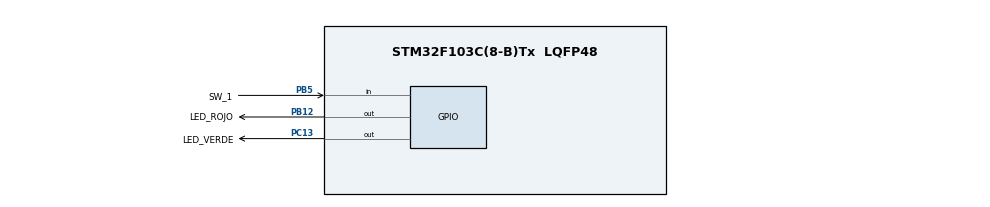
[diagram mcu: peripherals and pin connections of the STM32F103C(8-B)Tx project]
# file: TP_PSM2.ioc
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Mcu.Family=STM32F1
Mcu.Name=STM32F103C(8-B)Tx
Mcu.Package=LQFP48
NVIC.PriorityGroup=NVIC_PRIORITYGROUP_4
PA13.Mode=Serial_Wire
PA13.Signal=SYS_JTMS-SWDIO
PA14.Mode=Serial_Wire
PA14.Signal=SYS_JTCK-SWCLK
PB12.GPIO_Label=LED_ROJO
PB12.GPIO_PuPd=GPIO_NOPULL
PB12.Signal=GPIO_Output
PB5.GPIO_Label=SW_1
PB5.GPIO_PuPd=GPIO_PULLDOWN
PB5.Signal=GPIO_Input
PC13-TAMPER-RTC.GPIO_Label=LED_VERDE
PC13-TAMPER-RTC.GPIO_PuPd=GPIO_NOPULL
PC13-TAMPER-RTC.Signal=GPIO_Output
ProjectManager.HeapSize=0x200
ProjectManager.StackSize=0x400
ProjectManager.TargetToolchain=STM32CubeIDE
RCC.APB1Freq_Value=8000000
RCC.APB2Freq_Value=8000000
board=custom

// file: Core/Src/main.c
/* USER CODE BEGIN Header */
/**
  ******************************************************************************
  * @file           : main.c
  * @brief          : Main program body
  ******************************************************************************
  * @attention
  *
  * Copyright (c) 2024 STMicroelectronics.
  * All rights reserved.
  *
  ******************************************************************************
  */
/* USER CODE END Header */
#include "main.h"

/* USER CODE BEGIN Includes */
#include "fsm.h"
#include "timer.h"
/* USER CODE END Includes */

Semaforo semaforo;
Timer timer;  // Timer utilizado para manejar tiempos de transición

void SystemClock_Config(void);
static void MX_GPIO_Init(void);

/* USER CODE BEGIN 0 */

/***********************************************
*        PASO 4: FUNCIONES DE TRANSICIÓN       *
***********************************************/

/**
 * @brief Condición para pasar de verde a verde parpadeante.
 */
static int condicion_verde_a_verde_parpadeo(void *context) {
    Semaforo *semaforo = (Semaforo *)context;
    return (semaforo->fsm.currentState == ESTADO_VERDE) &&
           (HAL_GPIO_ReadPin(semaforo->PortSwitch, semaforo->PinSwitch) == GPIO_PIN_SET);
}

/**
 * @brief Condición para pasar de verde parpadeante a rojo.
 */
static int condicion_verde_parpadeo_a_rojo(void *context) {
    Semaforo *semaforo = (Semaforo *)context;
    return timer_has_expired(semaforo->timer);
}

/**
 * @brief Condición para pasar de rojo a rojo parpadeante.
 */
static int condicion_rojo_a_rojo_parpadeo(void *context) {
    Semaforo *semaforo = (Semaforo *)context;
    return timer_has_expired(semaforo->timer);
}

/**
 * @brief Condición para pasar de rojo parpadeante a verde.
 */
static int condicion_rojo_parpadeo_a_verde(void *context) {
    Semaforo *semaforo = (Semaforo *)context;
    return timer_has_expired(semaforo->timer);
}

/***********************************************
*          PASO 5: FUNCIONES DE ACCIÓN         *
***********************************************/

/**
 * @brief Acción al entrar en el estado verde.
 */
void on_state_verde(void *context) {
    Semaforo *semaforo = (Semaforo *)context;
    HAL_GPIO_WritePin(semaforo->PortVerde, semaforo->PinVerde, GPIO_PIN_RESET);
    HAL_GPIO_WritePin(semaforo->PortRojo, semaforo->PinRojo, GPIO_PIN_SET);
}

/**
 * @brief Acción al entrar en el estado verde parpadeante.
 */
void on_state_verde_parpadeo(void *context) {
    Semaforo *semaforo = (Semaforo *)context;
    timer_start(semaforo->timer, 1000); // Parpadeo durante 1 segundo
}

/**
 * @brief Acción al entrar en el estado rojo.
 */
void on_state_rojo(void *context) {
    Semaforo *semaforo = (Semaforo *)context;
    HAL_GPIO_WritePin(semaforo->PortVerde, semaforo->PinVerde, GPIO_PIN_SET);
    HAL_GPIO_WritePin(semaforo->PortRojo, semaforo->PinRojo, GPIO_PIN_RESET);
    timer_start(semaforo->timer, 3000); // Estado rojo durante 3 segundos
}

/**
 * @brief Acción al entrar en el estado rojo parpadeante.
 */
void on_state_rojo_parpadeo(void *context) {
    Semaforo *semaforo = (Semaforo *)context;
    timer_start(semaforo->timer, 1000); // Parpadeo rojo durante 1 segundo
}

/***********************************************
*          PASO 6: DECLARAR TRANSICIONES       *
***********************************************/

static Transition VerdeTransitions[] = {
    {condicion_verde_a_verde_parpadeo, ESTADO_VERDE_PARPADEO}
};

static Transition VerdeParpadeoTransitions[] = {
    {condicion_verde_parpadeo_a_rojo, ESTADO_ROJO}
};

static Transition RojoTransitions[] = {
    {condicion_rojo_a_rojo_parpadeo, ESTADO_ROJO_PARPADEO}
};

static Transition RojoParpadeoTransitions[] = {
    {condicion_rojo_parpadeo_a_verde, ESTADO_VERDE}
};

/***********************************************
*           PASO 7: ENSAMBLAR EL MÓDULO        *
***********************************************/

static FSMState SemaforoEstados[] = {
    {VerdeTransitions, 1, on_state_verde},
    {VerdeParpadeoTransitions, 1, on_state_verde_parpadeo},
    {RojoTransitions, 1, on_state_rojo},
    {RojoParpadeoTransitions, 1, on_state_rojo_parpadeo}
};

/***********************************************
*         PASO 8: INICIALIZAR EL MÓDULO        *
***********************************************/

/**
 * @brief Inicializa el módulo de semáforo.
 */
void semaforo_init(Semaforo *semaforo, GPIO_TypeDef *PortVerde, uint16_t PinVerde,
                   GPIO_TypeDef *PortRojo, uint16_t PinRojo,
                   GPIO_TypeDef *PortSwitch, uint16_t PinSwitch) {
    fsm_init(&semaforo->fsm, SemaforoEstados, ESTADO_VERDE, semaforo);
    semaforo->PortVerde = PortVerde;
    semaforo->PinVerde = PinVerde;
    semaforo->PortRojo = PortRojo;
    semaforo->PinRojo = PinRojo;
    semaforo->PortSwitch = PortSwitch;
    semaforo->PinSwitch = PinSwitch;
    on_state_verde(semaforo); // Establece el estado inicial en verde
}

/***********************************************
*         PASO 9: ACTUALIZAR EL MÓDULO         *
***********************************************/

/**
 * @brief Actualiza el módulo de semáforo.
 */
void semaforo_update(Semaforo *semaforo) {
    fsm_update(&semaforo->fsm);
}

/* USER CODE END 0 */

int main(void)
{
  /* USER CODE BEGIN 1 */
  semaforo.timer = &timer;
  /* USER CODE END 1 */

  /* MCU Configuration--------------------------------------------------------*/

  HAL_Init();
  SystemClock_Config();
  MX_GPIO_Init();

  /* USER CODE BEGIN 2 */
  semaforo_init(&semaforo, LED_VERDE_GPIO_Port, LED_VERDE_Pin, LED_ROJO_GPIO_Port, LED_ROJO_Pin, SW_1_GPIO_Port, SW_1_Pin);
  /* USER CODE END 2 */

  /* Infinite loop */
  while (1)
  {
    /* USER CODE BEGIN WHILE */
    semaforo_update(&semaforo);
    /* USER CODE END WHILE */
  }
}

void SystemClock_Config(void)
{
  RCC_OscInitTypeDef RCC_OscInitStruct = {0};
  RCC_ClkInitTypeDef RCC_ClkInitStruct = {0};

  RCC_OscInitStruct.OscillatorType = RCC_OSCILLATORTYPE_HSI;
  RCC_OscInitStruct.HSIState = RCC_HSI_ON;
  RCC_OscInitStruct.HSICalibrationValue = RCC_HSICALIBRATION_DEFAULT;
  RCC_OscInitStruct.PLL.PLLState = RCC_PLL_NONE;
  if (HAL_RCC_OscConfig(&RCC_OscInitStruct) != HAL_OK)
  {
    Error_Handler();
  }

  RCC_ClkInitStruct.ClockType = RCC_CLOCKTYPE_HCLK|RCC_CLOCKTYPE_SYSCLK
                              |RCC_CLOCKTYPE_PCLK1|RCC_CLOCKTYPE_PCLK2;
  RCC_ClkInitStruct.SYSCLKSource = RCC_SYSCLKSOURCE_HSI;
  RCC_ClkInitStruct.AHBCLKDivider = RCC_SYSCLK_DIV1;
  RCC_ClkInitStruct.APB1CLKDivider = RCC_HCLK_DIV1;
  RCC_ClkInitStruct.APB2CLKDivider = RCC_HCLK_DIV1;

  if (HAL_RCC_ClockConfig(&RCC_ClkInitStruct, FLASH_LATENCY_0) != HAL_OK)
  {
    Error_Handler();
  }
}

static void MX_GPIO_Init(void)
{
  GPIO_InitTypeDef GPIO_InitStruct = {0};

  __HAL_RCC_GPIOC_CLK_ENABLE();
  __HAL_RCC_GPIOB_CLK_ENABLE();
  __HAL_RCC_GPIOA_CLK_ENABLE();

  HAL_GPIO_WritePin(LED_VERDE_GPIO_Port, LED_VERDE_Pin, GPIO_PIN_RESET);
  HAL_GPIO_WritePin(LED_ROJO_GPIO_Port, LED_ROJO_Pin, GPIO_PIN_RESET);

  GPIO_InitStruct.Pin = LED_VERDE_Pin;
  GPIO_InitStruct.Mode = GPIO_MODE_OUTPUT_PP;
  GPIO_InitStruct.Pull = GPIO_NOPULL;
  GPIO_InitStruct.Speed = GPIO_SPEED_FREQ_LOW;
  HAL_GPIO_Init(LED_VERDE_GPIO_Port, &GPIO_InitStruct);

  GPIO_InitStruct.Pin = LED_ROJO_Pin;
  GPIO_InitStruct.Mode = GPIO_MODE_OUTPUT_PP;
  GPIO_InitStruct.Pull = GPIO_NOPULL;
  GPIO_InitStruct.Speed = GPIO_SPEED_FREQ_LOW;
  HAL_GPIO_Init(LED_ROJO_GPIO_Port, &GPIO_InitStruct);

  GPIO_InitStruct.Pin = SW_1_Pin;
  GPIO_InitStruct.Mode = GPIO_MODE_INPUT;
  GPIO_InitStruct.Pull = GPIO_PULLDOWN;
  HAL_GPIO_Init(SW_1_GPIO_Port, &GPIO_InitStruct);
}

void Error_Handler(void)
{
  __disable_irq();
  while (1)
  {
  }
}
